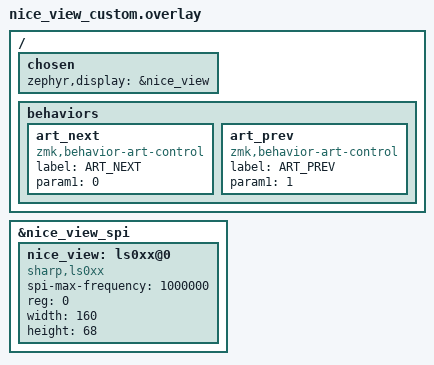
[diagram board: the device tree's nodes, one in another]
/*
 * Copyright (c) 2022 The ZMK Contributors
 *
 * SPDX-License-Identifier: MIT
 */

&nice_view_spi {
    status = "okay";
    nice_view: ls0xx@0 {
        compatible = "sharp,ls0xx";
        spi-max-frequency = <1000000>;
        reg = <0>;
        width = <160>;
        height = <68>;
    };
};

/ {
    chosen {
        zephyr,display = &nice_view;
    };

    behaviors {
        art_next: art_next {
            compatible = "zmk,behavior-art-control";
            label = "ART_NEXT";
            #binding-cells = <0>;
            param1 = <0>;
        };

        art_prev: art_prev {
            compatible = "zmk,behavior-art-control";
            label = "ART_PREV";
            #binding-cells = <0>;
            param1 = <1>;
        };
    };
};
